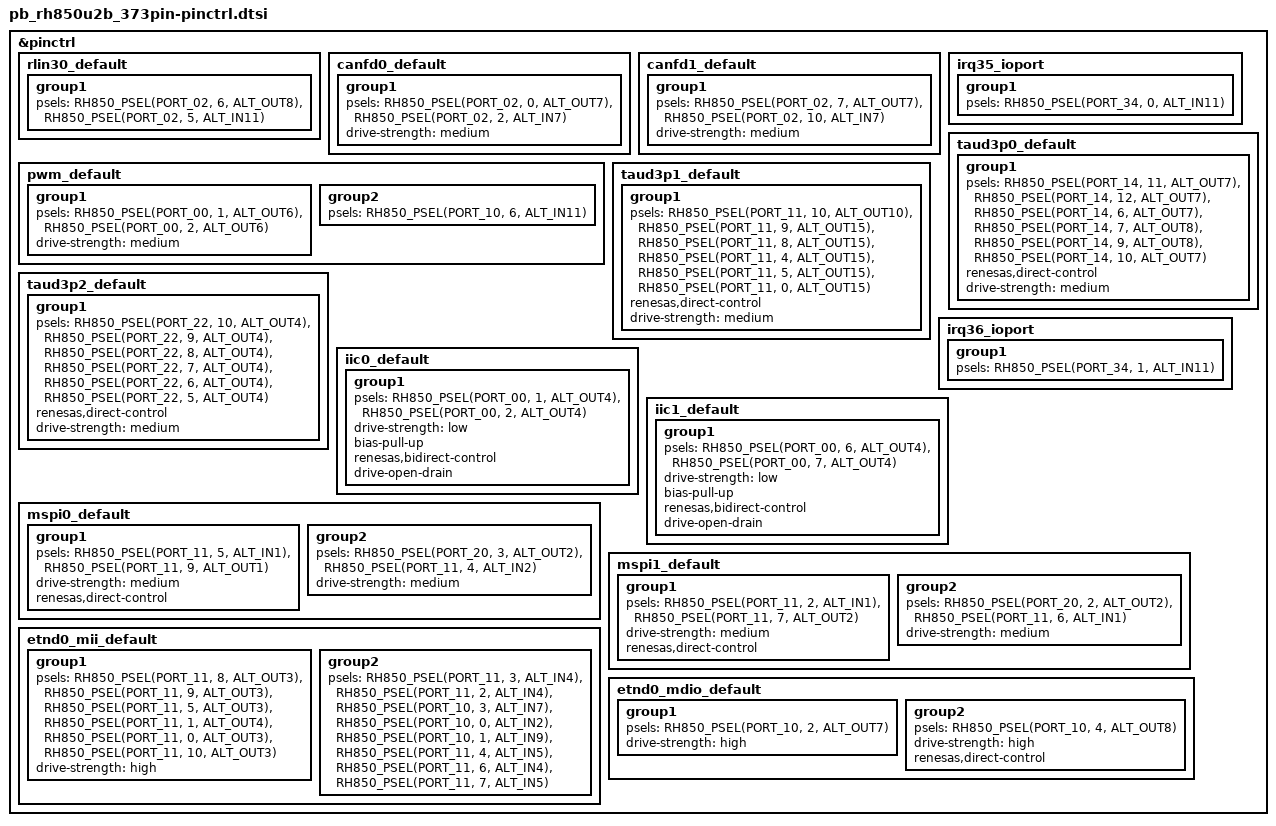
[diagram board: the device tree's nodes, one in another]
/*
 * Copyright (c) 2026 Renesas Electronics Corporation
 * SPDX-License-Identifier: Apache-2.0
 */

#include <dt-bindings/pinctrl/renesas/pinctrl-rh850u2b.h>

&pinctrl {
	rlin30_default: rlin30_default {
		group1 {
			psels = <RH850_PSEL(PORT_02, 6, ALT_OUT8)>,
				<RH850_PSEL(PORT_02, 5, ALT_IN11)>;
		};
	};

	canfd0_default: canfd0_default {
		group1 {
			psels = <RH850_PSEL(PORT_02, 0, ALT_OUT7)>,	/* TX */
				<RH850_PSEL(PORT_02, 2, ALT_IN7)>;	/* RX */
			drive-strength = "medium";
		};
	};

	canfd1_default: canfd1_default {
		group1 {
			psels = <RH850_PSEL(PORT_02, 7, ALT_OUT7)>,	/* TX */
				<RH850_PSEL(PORT_02, 10, ALT_IN7)>;	/* RX */
			drive-strength = "medium";
		};
	};

	irq35_ioport: irq35_ioport {
		group1 {
			psels = <RH850_PSEL(PORT_34, 0, ALT_IN11)>;
		};
	};

	pwm_default: pwm_default {
		group1 {
			psels = <RH850_PSEL(PORT_00, 1, ALT_OUT6)>,	/* ch1 */
				<RH850_PSEL(PORT_00, 2, ALT_OUT6)>;	/* ch2 */
			drive-strength = "medium";
		};

		group2 {
			psels = <RH850_PSEL(PORT_10, 6, ALT_IN11)>;	/* ch6 */
		};
	};

	taud3p0_default: taud3p0_default {
		group1 {
			psels = <RH850_PSEL(PORT_14, 11, ALT_OUT7)>,  /* U high */
				<RH850_PSEL(PORT_14, 12, ALT_OUT7)>,  /* U low  */
				<RH850_PSEL(PORT_14, 6,  ALT_OUT7)>,  /* V high */
				<RH850_PSEL(PORT_14, 7,  ALT_OUT8)>,  /* V low  */
				<RH850_PSEL(PORT_14, 9,  ALT_OUT8)>,  /* W high */
				<RH850_PSEL(PORT_14, 10, ALT_OUT7)>;  /* W low  */
			renesas,direct-control;
			drive-strength = "medium";
		};
	};

	taud3p1_default: taud3p1_default {
		group1 {
			psels = <RH850_PSEL(PORT_11, 10, ALT_OUT10)>, /* U high */
				<RH850_PSEL(PORT_11, 9,  ALT_OUT15)>, /* U low  */
				<RH850_PSEL(PORT_11, 8,  ALT_OUT15)>, /* V high */
				<RH850_PSEL(PORT_11, 4,  ALT_OUT15)>, /* V low  */
				<RH850_PSEL(PORT_11, 5,  ALT_OUT15)>, /* W high */
				<RH850_PSEL(PORT_11, 0,  ALT_OUT15)>; /* W low  */
			renesas,direct-control;
			drive-strength = "medium";
		};
	};

	taud3p2_default: taud3p2_default {
		group1 {
			psels = <RH850_PSEL(PORT_22, 10, ALT_OUT4)>, /* U high */
				<RH850_PSEL(PORT_22, 9,  ALT_OUT4)>, /* U low  */
				<RH850_PSEL(PORT_22, 8,  ALT_OUT4)>, /* V high */
				<RH850_PSEL(PORT_22, 7,  ALT_OUT4)>, /* V low  */
				<RH850_PSEL(PORT_22, 6,  ALT_OUT4)>, /* W high */
				<RH850_PSEL(PORT_22, 5,  ALT_OUT4)>; /* W low  */
			renesas,direct-control;
			drive-strength = "medium";
		};
	};

	irq36_ioport: irq36_ioport {
		group1 {
			psels = <RH850_PSEL(PORT_34, 1, ALT_IN11)>;
		};
	};

	iic0_default: iic0_default {
		group1 {
			psels = <RH850_PSEL(PORT_00, 1, ALT_OUT4)>,
				<RH850_PSEL(PORT_00, 2, ALT_OUT4)>;
			drive-strength = "low";
			bias-pull-up;
			renesas,bidirect-control;
			drive-open-drain;
		};
	};

	iic1_default: iic1_default {
		group1 {
			psels = <RH850_PSEL(PORT_00, 6, ALT_OUT4)>,
				<RH850_PSEL(PORT_00, 7, ALT_OUT4)>;
			drive-strength = "low";
			bias-pull-up;
			renesas,bidirect-control;
			drive-open-drain;
		};
	};

	mspi0_default: mspi0_default {
		group1 {
			psels = <RH850_PSEL(PORT_11, 5, ALT_IN1)>,
				<RH850_PSEL(PORT_11, 9, ALT_OUT1)>;
			drive-strength = "medium";
			renesas,direct-control;
		};

		group2 {
			psels = <RH850_PSEL(PORT_20, 3, ALT_OUT2)>,
				<RH850_PSEL(PORT_11, 4, ALT_IN2)>;
			drive-strength = "medium";
		};
	};

	mspi1_default: mspi1_default {
		group1 {
			psels = <RH850_PSEL(PORT_11, 2, ALT_IN1)>,
				<RH850_PSEL(PORT_11, 7, ALT_OUT2)>;
			drive-strength = "medium";
			renesas,direct-control;
		};

		group2 {
			psels = <RH850_PSEL(PORT_20, 2, ALT_OUT2)>,
				<RH850_PSEL(PORT_11, 6, ALT_IN1)>;
			drive-strength = "medium";
		};
	};

	etnd0_mii_default: etnd0_mii_default {
		group1 {
			psels = <RH850_PSEL(PORT_11, 8, ALT_OUT3)>,	/* ETH0_MII_TXD0 */
				<RH850_PSEL(PORT_11, 9, ALT_OUT3)>,	/* ETH0_MII_TXD1 */
				<RH850_PSEL(PORT_11, 5, ALT_OUT3)>,	/* ETH0_MII_TXD2 */
				<RH850_PSEL(PORT_11, 1, ALT_OUT4)>,	/* ETH0_MII_TXD3 */
				<RH850_PSEL(PORT_11, 0, ALT_OUT3)>,	/* ETH0_MII_TX_EN */
				<RH850_PSEL(PORT_11, 10, ALT_OUT3)>;	/* ETH0_MII_TX_ER */
			drive-strength = "high";
		};

		group2 {
			psels = <RH850_PSEL(PORT_11, 3, ALT_IN4)>,	/* ETH0_MII_RXD0 */
				<RH850_PSEL(PORT_11, 2, ALT_IN4)>,	/* ETH0_MII_RXD1 */
				<RH850_PSEL(PORT_10, 3, ALT_IN7)>,	/* ETH0_MII_RXD2 */
				<RH850_PSEL(PORT_10, 0, ALT_IN2)>,	/* ETH0_MII_RXD3 */
				<RH850_PSEL(PORT_10, 1, ALT_IN9)>,	/* ETH0_MII_RX_CLK */
				<RH850_PSEL(PORT_11, 4, ALT_IN5)>,	/* ETH0_MII_TX_CLK */
				<RH850_PSEL(PORT_11, 6, ALT_IN4)>,	/* ETH0_MII_RX_ER */
				<RH850_PSEL(PORT_11, 7, ALT_IN5)>;	/* ETH0_MII_RX_DV */
		};
	};

	etnd0_mdio_default: etnd0_mdio_default {
		group1 {
			psels = <RH850_PSEL(PORT_10, 2, ALT_OUT7)>; /* ETH0_MDC */
			drive-strength = "high";
		};

		group2 {
			psels = <RH850_PSEL(PORT_10, 4, ALT_OUT8)>; /* ETH0_MDIO */
			drive-strength = "high";
			renesas,direct-control;
		};
	};
};
